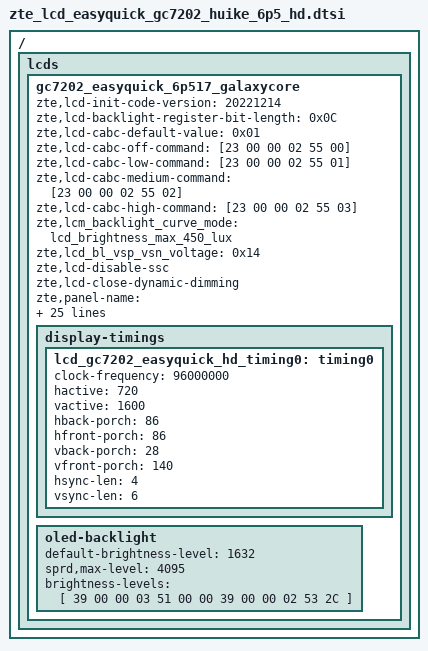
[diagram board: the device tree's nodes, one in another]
/ {
	fragment {
		target-path = "/";
		__overlay__ {
 lcds {
	gc7202_easyquick_6p517_galaxycore: gc7202_easyquick_6p517_galaxycore {
		zte,lcd-init-code-version = "20221214";
		zte,lcd-backlight-register-bit-length = <0x0C>;
		zte,lcd-cabc-default-value = <0x01>;
		zte,lcd-cabc-off-command = [23 00 00 02 55 00];
		zte,lcd-cabc-low-command = [23 00 00 02 55 01];
		zte,lcd-cabc-medium-command = [23 00 00 02 55 02];
		zte,lcd-cabc-high-command = [23 00 00 02 55 03];
		zte,lcm_backlight_curve_mode = "lcd_brightness_max_450_lux";
		zte,lcd_bl_vsp_vsn_voltage = <0x14>;
		zte,lcd-disable-ssc;
		zte,lcd-close-dynamic-dimming;
		zte,panel-name = "gc7202_easyquick_6p517_galaxycore";
		zte,lcd-delay-open-bl-value = <34>;

		sprd,dsi-work-mode = <1>; /* video burst mode*/
		sprd,dsi-lane-number = <4>;
		sprd,dsi-color-format = "rgb888";

		sprd,phy-bit-clock = <700000>;	/* kbps */
		sprd,phy-escape-clock = <20000>;/* kHz */

		sprd,width-mm = <67932>;
		sprd,height-mm = <150960>;

		sprd,esd-check-enable = <1>;/* 0:close , 1:open */
		sprd,esd-check-mode = <1>;/* 0:REG ,1:TE  */
		sprd,esd-check-period = <1000>;
		sprd,esd-check-register = <0x0A>;
		sprd,esd-check-value = <0x9C>;

		sprd,reset-on-sequence = <1 10>, <0 10>, <1 35>, <0 10>, <1 10>, <0 10>, <1 10>, <0 10>, <1 30>;
		sprd,reset-off-sequence = <1 5>;
		sprd,initial-command = [
39 00 00 04 FF 55 AA 66
15 00 00 02 FF 20
15 00 00 02 FB 00
15 00 00 02 FF 21
15 00 00 02 FB 00
15 00 00 02 FF 22
15 00 00 02 FB 00
15 00 00 02 FF 23
15 00 00 02 FB 00
15 00 00 02 FF 24
15 00 00 02 FB 00
15 00 00 02 FF 26
15 00 00 02 FB 00
15 00 00 02 FF 27
15 00 00 02 FB 00
15 00 00 02 FF A3
15 00 00 02 FB 00
15 00 00 02 FF B3
15 00 00 02 FB 00
15 00 00 02 FF C3
15 00 00 02 FB 00
15 00 00 02 FF 10
15 00 00 02 FB 00
15 00 00 02 FF 20
15 00 00 02 18 44
15 00 00 02 17 52
15 00 00 02 15 5D
15 00 00 02 12 A1
15 00 00 02 A5 00
15 00 00 02 A6 FF
15 00 00 02 A9 00
15 00 00 02 AA FF
15 00 00 02 D3 05
15 00 00 02 2D 1F
15 00 00 02 FF B3
15 00 00 02 58 84
15 00 00 02 82 1A
15 00 00 02 FF 22
15 00 00 02 1F 06
15 00 00 02 FF C3
15 00 00 02 06 44
15 00 00 02 13 07
15 00 00 02 FF 20
15 00 00 02 A3 44
15 00 00 02 A7 44
15 00 00 02 FF B3
15 00 00 02 3F 37
15 00 00 02 5E 10
15 00 00 02 FF 22
15 00 00 02 E4 01
15 00 00 02 01 06
15 00 00 02 02 40
15 00 00 02 25 08
15 00 00 02 26 00
15 00 00 02 2E 8F
15 00 00 02 2F 00
15 00 00 02 36 0A
15 00 00 02 37 00
15 00 00 02 3F 8F
15 00 00 02 40 00
15 00 00 02 DC 00
15 00 00 02 E0 07 /*PWM OUTPUT*/
15 00 00 02 FF 21
15 00 00 02 01 25
15 00 00 02 02 25
15 00 00 02 03 23
15 00 00 02 04 23
15 00 00 02 05 1B
15 00 00 02 06 03
15 00 00 02 07 18
15 00 00 02 08 19
15 00 00 02 09 1A
15 00 00 02 0A 09
15 00 00 02 0B 0B
15 00 00 02 0C 0D
15 00 00 02 0D 0F
15 00 00 02 0E 01
15 00 00 02 0F 25
15 00 00 02 10 25
15 00 00 02 11 25
15 00 00 02 12 25
15 00 00 02 13 25
15 00 00 02 14 25
15 00 00 02 15 25
15 00 00 02 16 25
15 00 00 02 17 23
15 00 00 02 18 23
15 00 00 02 19 23
15 00 00 02 1A 23
15 00 00 02 1B 1B
15 00 00 02 1C 02
15 00 00 02 1D 18
15 00 00 02 1E 19
15 00 00 02 1F 1A
15 00 00 02 20 08
15 00 00 02 21 0A
15 00 00 02 22 0C
15 00 00 02 23 0E
15 00 00 02 24 00
15 00 00 02 25 25
15 00 00 02 26 25
15 00 00 02 27 25
15 00 00 02 28 25
15 00 00 02 29 25
15 00 00 02 2A 25
15 00 00 02 2B 25
15 00 00 02 2D 25
15 00 00 02 7E 03
15 00 00 02 7F 23
15 00 00 02 8B 23
15 00 00 02 80 07
15 00 00 02 8C 03
15 00 00 02 81 03
15 00 00 02 8D 07
15 00 00 02 AF 40
15 00 00 02 B0 40
15 00 00 02 83 02
15 00 00 02 8F 02
15 00 00 02 84 26
15 00 00 02 90 26
15 00 00 02 85 5A
15 00 00 02 91 5A
15 00 00 02 87 02
15 00 00 02 93 06
15 00 00 02 82 B0
15 00 00 02 8E B0
15 00 00 02 2E 00
15 00 00 02 88 A7
15 00 00 02 89 20
15 00 00 02 8A 33
15 00 00 02 94 A7
15 00 00 02 95 20
15 00 00 02 96 33
15 00 00 02 45 0F
15 00 00 02 46 B5
15 00 00 02 4C B5
15 00 00 02 52 B5
15 00 00 02 58 B5
15 00 00 02 47 0A
15 00 00 02 4D 09
15 00 00 02 53 23
15 00 00 02 59 24
15 00 00 02 48 24
15 00 00 02 4E 23
15 00 00 02 54 09
15 00 00 02 5A 0A
15 00 00 02 76 40
15 00 00 02 77 40
15 00 00 02 78 40
15 00 00 02 79 40
15 00 00 02 49 26
15 00 00 02 4A 5A
15 00 00 02 4F 26
15 00 00 02 50 5A
15 00 00 02 55 5A
15 00 00 02 56 5A
15 00 00 02 5B 5A
15 00 00 02 5C 5A
15 00 00 02 BE 03
15 00 00 02 C0 44
15 00 00 02 C1 40
15 00 00 02 BF BB
15 00 00 02 C2 8B
15 00 00 02 C3 8B
15 00 00 02 C6 42
15 00 00 02 C7 54
15 00 00 02 D1 03
15 00 00 02 FF 22
15 00 00 02 05 10
15 00 00 02 08 23
15 00 00 02 FF 20
15 00 00 02 25 12
15 00 00 02 FF 20
15 00 00 02 C3 00
15 00 00 02 C4 5F
15 00 00 02 C5 00
15 00 00 02 C6 5F
15 00 00 02 B3 00
15 00 00 02 B4 20
15 00 00 02 B5 00
15 00 00 02 B6 DC
15 00 00 02 FF 20
15 00 00 02 02 33
15 00 00 02 03 33
15 00 00 02 04 4E
15 00 00 02 05 4E
15 00 00 02 0A 31
15 00 00 02 0B 31
15 00 00 02 0C 4C
15 00 00 02 0D 4C
15 00 00 02 77 99
15 00 00 02 78 A0
15 00 00 02 7E 01
15 00 00 02 7F 00
15 00 00 02 80 01
15 00 00 02 81 00
15 00 00 02 82 00
15 00 00 02 83 04
15 00 00 02 84 04
15 00 00 02 85 01
15 00 00 02 86 87
15 00 00 02 87 01
15 00 00 02 88 87
15 00 00 02 8A 03
15 00 00 02 8B 03
15 00 00 02 FF 20
15 00 00 02 50 0F
15 00 00 02 51 22
15 00 00 02 FF 23
15 00 00 02 25 03
39 00 00 11 01 00 00 00 0F 00 43 00 5F 00 77 00 89 00 9A 00 A8
39 00 00 11 02 00 B8 00 E0 01 05 01 3C 01 66 01 A8 01 E3 01 E5
39 00 00 11 03 02 24 02 70 02 A1 02 E1 03 0A 03 40 03 4F 03 61
39 00 00 0D 04 03 74 03 8B 03 A5 03 C3 03 E9 03 FF
39 00 00 11 0D 00 00 00 0F 00 43 00 5F 00 77 00 89 00 9A 00 A8
39 00 00 11 0E 00 B8 00 E0 01 05 01 3C 01 66 01 A8 01 E3 01 E5
39 00 00 11 0F 02 24 02 70 02 A1 02 E1 03 0A 03 40 03 4F 03 61
39 00 00 0D 10 03 74 03 8B 03 A5 03 C3 03 E9 03 FF
15 00 00 02 2E 20
15 00 00 02 32 01
15 00 00 02 33 3F/*PWM频率为20KHz*/
15 00 00 02 FF 22
15 00 00 02 EF 01
15 00 00 02 FF 10
39 00 00 03 51 00 00 /*默认PWM占空比为0*/
15 00 00 02 53 2C
15 00 00 02 55 00
15 00 00 02 36 08
15 00 00 02 69 00
15 00 00 02 35 00
05 78 00 01 11 
15 00 00 02 FF 27
39 00 00 07 03 40 10 08 00 F3 0C
39 00 00 0E 04 03 24 80 44 4C 54 AD 05 00 00 1C E0 10
15 00 00 02 FF 10
05 14 00 01 29
			];
		sprd,sleep-in-command = [
39 00 00 04 FF 55 AA 66
15 00 00 02 FF 20
15 00 00 02 4A 01
15 00 00 02 48 10
15 00 00 02 49 00
15 00 00 02 FF A3
15 00 00 02 0F 01
15 00 00 02 0E 03
15 00 00 02 FF 10
15 32 00 02 28 00
15 78 00 02 10 00
15 00 00 02 FF A3
15 00 00 02 0F 00
15 00 00 02 0E 00
39 00 00 04 FF 55 AA 66
15 00 00 02 FF 26
15 00 00 02 FB 00
39 00 00 05 1D A2 AA AA 0A
15 00 00 02 FF 10
15 00 00 02 FB 00
15 0A 00 02 4F 01
			];
		sprd,sleep-in-gesture-command = [
39 00 00 04 FF 55 AA 66
15 00 00 02 FF 20
15 00 00 02 4A 01
15 00 00 02 48 10
15 00 00 02 49 00
15 00 00 02 FF A3
15 00 00 02 0F 01
15 00 00 02 0E 03
15 00 00 02 FF 10
15 32 00 02 28 00
15 78 00 02 10 00
15 00 00 02 FF A3
15 00 00 02 0F 00
15 0A 00 02 0E 00
			];
		sprd,sleep-out-command = [
			05 78 00 01 11
			05 32 00 01 29
			];

		display-timings {
			lcd_gc7202_easyquick_hd_timing0: timing0 {
			clock-frequency = <96000000>;
			hactive = <720>;
			vactive = <1600>;
			hback-porch = <86>;
			hfront-porch = <86>;
			vback-porch = <28>;
			vfront-porch = <140>;
			hsync-len = <4>;
			vsync-len = <6>;
			};
		};

		oled-backlight {
			default-brightness-level = <1632>;
			sprd,max-level = <4095>;
			brightness-levels = [
				39 00 00 03 51 00 00
				39 00 00 02 53 2C
			];
		};
	};
};};
};};
